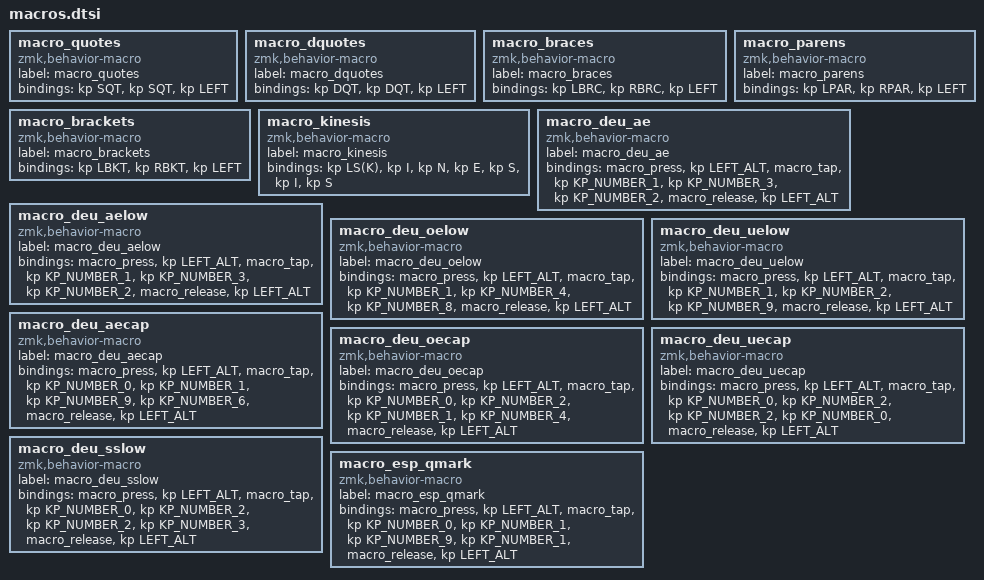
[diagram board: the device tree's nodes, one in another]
macro_quotes: macro_quotes{
compatible = "zmk,behavior-macro";
label = "macro_quotes";
#binding-cells = <0>;
bindings = <&kp SQT>, <&kp SQT>, <&kp LEFT>;
};
macro_dquotes: macro_dquotes{
compatible = "zmk,behavior-macro";
label = "macro_dquotes";
#binding-cells = <0>;
bindings = <&kp DQT>, <&kp DQT>, <&kp LEFT>;
};
macro_braces: macro_braces{
compatible = "zmk,behavior-macro";
label = "macro_braces";
#binding-cells = <0>;
bindings = <&kp LBRC>, <&kp RBRC>, <&kp LEFT>;
};
macro_parens: macro_parens{
compatible = "zmk,behavior-macro";
label = "macro_parens";
#binding-cells = <0>;
bindings = <&kp LPAR>, <&kp RPAR>, <&kp LEFT>;
};
macro_brackets: macro_brackets{
compatible = "zmk,behavior-macro";
label = "macro_brackets";
#binding-cells = <0>;
bindings = <&kp LBKT>, <&kp RBKT>, <&kp LEFT>;
};
macro_kinesis: macro_kinesis{
compatible = "zmk,behavior-macro";
label = "macro_kinesis";
#binding-cells = <0>;
bindings = <&kp LS(K)>, <&kp I>, <&kp N>, <&kp E>, <&kp S>, <&kp I>, <&kp S>;
};

  macro_deu_ae: macro_deu_ae {
    compatible = "zmk,behavior-macro";
    label = "macro_deu_ae";
    #binding-cells = <0>;
    bindings
      = <&macro_press &kp LEFT_ALT>
      , <&macro_tap &kp KP_NUMBER_1 &kp KP_NUMBER_3 &kp KP_NUMBER_2>
      , <&macro_release &kp LEFT_ALT>
      ;
  };
  

macro_deu_aelow: macro_deu_aelow {
  compatible = "zmk,behavior-macro";
  label = "macro_deu_aelow";
  #binding-cells = <0>;
  bindings
    = <&macro_press &kp LEFT_ALT>
    , <&macro_tap &kp KP_NUMBER_1 &kp KP_NUMBER_3 &kp KP_NUMBER_2>
    , <&macro_release &kp LEFT_ALT>
    ;
};
macro_deu_oelow: macro_deu_oelow {
  compatible = "zmk,behavior-macro";
  label = "macro_deu_oelow";
  #binding-cells = <0>;
  bindings
    = <&macro_press &kp LEFT_ALT>
    , <&macro_tap &kp KP_NUMBER_1 &kp KP_NUMBER_4 &kp KP_NUMBER_8>
    , <&macro_release &kp LEFT_ALT>
    ;
};
macro_deu_uelow: macro_deu_uelow {
  compatible = "zmk,behavior-macro";
  label = "macro_deu_uelow";
  #binding-cells = <0>;
  bindings
    = <&macro_press &kp LEFT_ALT>
    , <&macro_tap &kp KP_NUMBER_1 &kp KP_NUMBER_2 &kp KP_NUMBER_9>
    , <&macro_release &kp LEFT_ALT>
    ;
};
macro_deu_aecap: macro_deu_aecap {
  compatible = "zmk,behavior-macro";
  label = "macro_deu_aecap";
  #binding-cells = <0>;
  bindings
    = <&macro_press &kp LEFT_ALT>
    , <&macro_tap &kp KP_NUMBER_0 &kp KP_NUMBER_1 &kp KP_NUMBER_9 &kp KP_NUMBER_6>
    , <&macro_release &kp LEFT_ALT>
    ;
};
macro_deu_oecap: macro_deu_oecap {
  compatible = "zmk,behavior-macro";
  label = "macro_deu_oecap";
  #binding-cells = <0>;
  bindings
    = <&macro_press &kp LEFT_ALT>
    , <&macro_tap &kp KP_NUMBER_0 &kp KP_NUMBER_2 &kp KP_NUMBER_1 &kp KP_NUMBER_4>
    , <&macro_release &kp LEFT_ALT>
    ;
};
macro_deu_uecap: macro_deu_uecap {
  compatible = "zmk,behavior-macro";
  label = "macro_deu_uecap";
  #binding-cells = <0>;
  bindings
    = <&macro_press &kp LEFT_ALT>
    , <&macro_tap &kp KP_NUMBER_0 &kp KP_NUMBER_2 &kp KP_NUMBER_2 &kp KP_NUMBER_0>
    , <&macro_release &kp LEFT_ALT>
    ;
};
macro_deu_sslow: macro_deu_sslow {
  compatible = "zmk,behavior-macro";
  label = "macro_deu_sslow";
  #binding-cells = <0>;
  bindings
    = <&macro_press &kp LEFT_ALT>
    , <&macro_tap &kp KP_NUMBER_0 &kp KP_NUMBER_2 &kp KP_NUMBER_2 &kp KP_NUMBER_3>
    , <&macro_release &kp LEFT_ALT>
    ;
};
macro_esp_qmark: macro_esp_qmark {
  compatible = "zmk,behavior-macro";
  label = "macro_esp_qmark";
  #binding-cells = <0>;
  bindings
    = <&macro_press &kp LEFT_ALT>
    , <&macro_tap &kp KP_NUMBER_0 &kp KP_NUMBER_1 &kp KP_NUMBER_9 &kp KP_NUMBER_1>
    , <&macro_release &kp LEFT_ALT>
    ;
};
